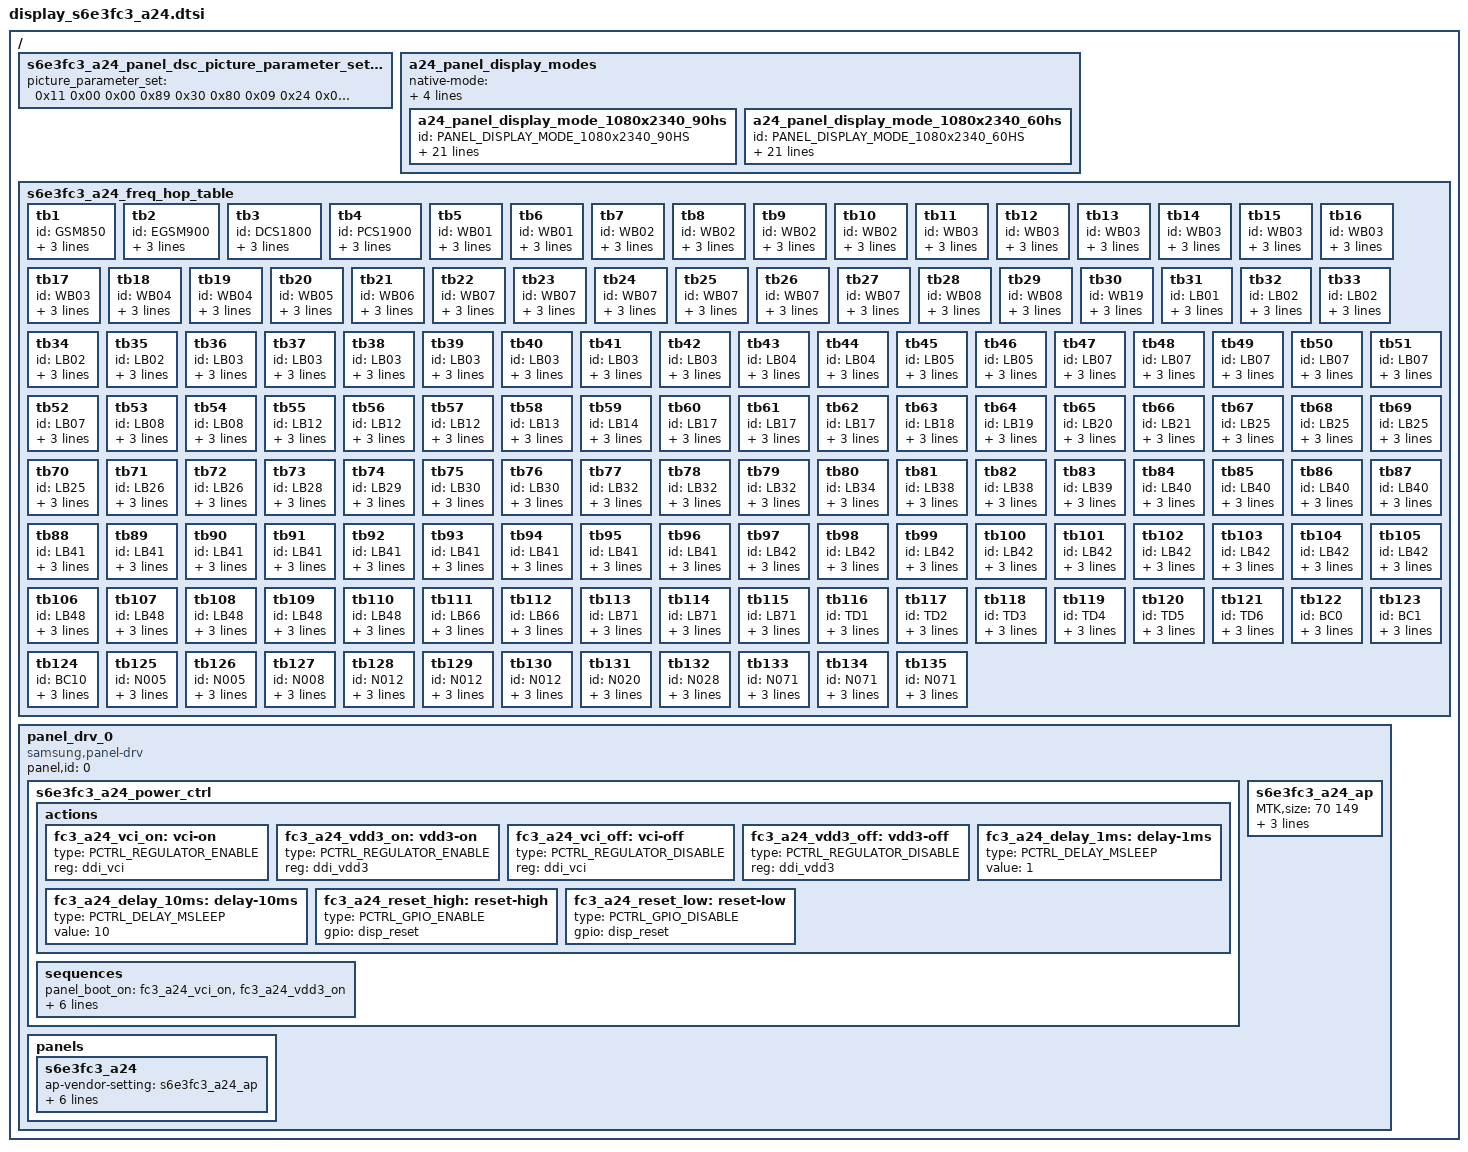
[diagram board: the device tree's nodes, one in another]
/*
 * Samsung Exynos SoC series Panel driver
 *
 * Copyright (c) 2020 Samsung Electronics Co., Ltd
 *
 * This program is free software; you can redistribute it and/or modify
 * it under the terms of the GNU General Public License version 2 as
 * published by the Free Software Foundation.
 */

#include <dt-bindings/display/panel-display.h>
#include <dt-bindings/display/rf-band-id.h>


/ {
	fragment@panel_display_mode {
		target-path = "/";
		__overlay__ {
			s6e3fc3_a24_panel_dsc_picture_parameter_set_default:
			s6e3fc3_a24_panel_dsc_picture_parameter_set_default {
					picture_parameter_set = /bits/ 8 <
						0x11 0x00 0x00 0x89 0x30 0x80 0x09 0x24
						0x04 0x38 0x00 0x1E 0x02 0x1C 0x02 0x1C
						0x02 0x00 0x02 0x0E 0x00 0x20 0x02 0xE3
						0x00 0x07 0x00 0x0C 0x03 0x50 0x03 0x64
						0x18 0x00 0x10 0xF0 0x03 0x0C 0x20 0x00
						0x06 0x0B 0x0B 0x33 0x0E 0x1C 0x2A 0x38
						0x46 0x54 0x62 0x69 0x70 0x77 0x79 0x7B
						0x7D 0x7E 0x01 0x02 0x01 0x00 0x09 0x40
						0x09 0xBE 0x19 0xFC 0x19 0xFA 0x19 0xF8
						0x1A 0x38 0x1A 0x78 0x1A 0xB6 0x2A 0xF6
						0x2B 0x34 0x2B 0x74 0x3B 0x74 0x6B 0xF4
						0x00 0x00 0x00 0x00 0x00 0x00 0x00 0x00
						0x00 0x00 0x00 0x00 0x00 0x00 0x00 0x00
						0x00 0x00 0x00 0x00 0x00 0x00 0x00 0x00
						0x00 0x00 0x00 0x00 0x00 0x00 0x00 0x00
						0x00 0x00 0x00 0x00 0x00 0x00 0x00 0x00
					>;
			};
			a24_panel_display_modes:
			a24_panel_display_modes {
				native-mode = <&a24_panel_display_mode_1080x2340_60hs>;
				exposed-mode = <
					&a24_panel_display_mode_1080x2340_60hs
					&a24_panel_display_mode_1080x2340_90hs
				>;

				/* fhd */
				a24_panel_display_mode_1080x2340_90hs:
				a24_panel_display_mode_1080x2340_90hs {
					id = PANEL_DISPLAY_MODE_1080x2340_90HS;
					width = <1080>;
					height = <2340>;
					/* timing parameters */
					refresh_rate = <90>;			/* logical refresh rate */
					refresh_mode = <REFRESH_MODE_HS>;
					panel_refresh_rate = <90>;		/* panel internal refresh rate */
					panel_refresh_mode = <PANEL_REFRESH_MODE_HS>;
					panel_te_st = <0>;				/* te rising */
					panel_te_ed = <0>;				/* te falling */
					panel_te_sw_skip_count = <0>;	/* s/w te modulation */
					panel_te_hw_skip_count = <0>;	/* h/w te modulation */
					panel_h_porch = <2 2 2>;
					panel_v_porch = <2 2 2>;	/* panel vbp:12, vfp:4, but for ap vblank set vbp:12+4, vfp:0 */
					/* dsc parameters */
					dsc_en = <1>;			/* 0:Disable, 1:Enable */
					dsc_cnt = <1>;			/* used DSC count */
					dsc_slice_num = <2>;	/* count of dsc slice */
					dsc_slice_w = <540>;	/* width of dsc slice */
					dsc_slice_h = <30>;	/* height of dsc slice */
					dsc_picture_parameter_set = <&s6e3fc3_a24_panel_dsc_picture_parameter_set_default>;

					/* dsi parameters */
					cmd_lp_ref = <2107>;
										/*qos parameters */
					disp_qos_fps = <90>;
				};

				a24_panel_display_mode_1080x2340_60hs:
				a24_panel_display_mode_1080x2340_60hs {
					id = PANEL_DISPLAY_MODE_1080x2340_60HS;
					width = <1080>;
					height = <2340>;
					/* timing parameters */
					refresh_rate = <60>;			/* logical refresh rate */
					refresh_mode = <REFRESH_MODE_HS>;
					panel_refresh_rate = <60>;		/* panel internal refresh rate */
					panel_refresh_mode = <PANEL_REFRESH_MODE_HS>;
					panel_te_st = <0>;				/* te rising */
					panel_te_ed = <0>;				/* te falling */
					panel_te_sw_skip_count = <0>;	/* s/w te modulation */
					panel_te_hw_skip_count = <0>;	/* h/w te modulation */
					panel_h_porch = <2 2 2>;
					panel_v_porch = <2 2 2>;	/* panel vbp:12, vfp:2420, but for ap vblank set vbp:12+2420, vfp:0 */
					/* dsc parameters */
					dsc_en = <1>;			/* 0:Disable, 1:Enable */
					dsc_cnt = <1>;			/* used DSC count */
					dsc_slice_num = <2>;	/* count of dsc slice */
					dsc_slice_w = <540>;	/* width of dsc slice */
					dsc_slice_h = <30>;	/* height of dsc slice */
					dsc_picture_parameter_set = <&s6e3fc3_a24_panel_dsc_picture_parameter_set_default>;
					/* dsi parameters */
					cmd_lp_ref = <7991>;
					/*qos parameters */
					disp_qos_fps = <90>;
				};


			};
		};
	};
};

/ {
	fragment@freq_hop {
		target-path = "/";
		__overlay__ {
			s6e3fc3_a24_freq_hop_table: s6e3fc3_a24_freq_hop_table {
				tb1 { id = <GSM850>; range = <0 0>; dsi_freq = <824000>; osc_freq = <0>; };
				tb2 { id = <EGSM900>; range = <0 0>; dsi_freq = <824000>; osc_freq = <0>; };
				tb3 { id = <DCS1800>; range = <0 0>; dsi_freq = <822000>; osc_freq = <0>; };
				tb4 { id = <PCS1900>; range = <0 0>; dsi_freq = <806000>; osc_freq = <0>; };
				tb5 { id = <WB01>; range = <10562 10653>; dsi_freq = <822000>; osc_freq = <0>; };
				tb6 { id = <WB01>; range = <10654 10838>; dsi_freq = <806000>; osc_freq = <0>; };
				tb7 { id = <WB02>; range = <9662 9709>; dsi_freq = <824000>; osc_freq = <0>; };
				tb8 { id = <WB02>; range = <9710 9836>; dsi_freq = <806000>; osc_freq = <0>; };
				tb9 { id = <WB02>; range = <9837 9859>; dsi_freq = <822000>; osc_freq = <0>; };
				tb10 { id = <WB02>; range = <9860 9938>; dsi_freq = <824000>; osc_freq = <0>; };
				tb11 { id = <WB03>; range = <1162 1267>; dsi_freq = <822000>; osc_freq = <0>; };
				tb12 { id = <WB03>; range = <1268 1272>; dsi_freq = <806000>; osc_freq = <0>; };
				tb13 { id = <WB03>; range = <1273 1297>; dsi_freq = <822000>; osc_freq = <0>; };
				tb14 { id = <WB03>; range = <1298 1319>; dsi_freq = <824000>; osc_freq = <0>; };
				tb15 { id = <WB03>; range = <1320 1447>; dsi_freq = <806000>; osc_freq = <0>; };
				tb16 { id = <WB03>; range = <1448 1469>; dsi_freq = <822000>; osc_freq = <0>; };
				tb17 { id = <WB03>; range = <1470 1513>; dsi_freq = <824000>; osc_freq = <0>; };
				tb18 { id = <WB04>; range = <1537 1628>; dsi_freq = <822000>; osc_freq = <0>; };
				tb19 { id = <WB04>; range = <1629 1738>; dsi_freq = <806000>; osc_freq = <0>; };
				tb20 { id = <WB05>; range = <4357 4458>; dsi_freq = <806000>; osc_freq = <0>; };
				tb21 { id = <WB06>; range = <4387 4413>; dsi_freq = <806000>; osc_freq = <0>; };
				tb22 { id = <WB07>; range = <2237 2297>; dsi_freq = <822000>; osc_freq = <0>; };
				tb23 { id = <WB07>; range = <2298 2342>; dsi_freq = <806000>; osc_freq = <0>; };
				tb24 { id = <WB07>; range = <2343 2407>; dsi_freq = <822000>; osc_freq = <0>; };
				tb25 { id = <WB07>; range = <2408 2439>; dsi_freq = <824000>; osc_freq = <0>; };
				tb26 { id = <WB07>; range = <2440 2557>; dsi_freq = <806000>; osc_freq = <0>; };
				tb27 { id = <WB07>; range = <2558 2563>; dsi_freq = <822000>; osc_freq = <0>; };
				tb28 { id = <WB08>; range = <2937 3000>; dsi_freq = <806000>; osc_freq = <0>; };
				tb29 { id = <WB08>; range = <3001 3088>; dsi_freq = <824000>; osc_freq = <0>; };
				tb30 { id = <WB19>; range = <712 763>; dsi_freq = <806000>; osc_freq = <0>; };
				tb31 { id = <LB01>; range = <0 599>; dsi_freq = <822000>; osc_freq = <0>; };
				tb32 { id = <LB02>; range = <600 719>; dsi_freq = <824000>; osc_freq = <0>; };
				tb33 { id = <LB02>; range = <720 972>; dsi_freq = <806000>; osc_freq = <0>; };
				tb34 { id = <LB02>; range = <973 1019>; dsi_freq = <822000>; osc_freq = <0>; };
				tb35 { id = <LB02>; range = <1020 1199>; dsi_freq = <824000>; osc_freq = <0>; };
				tb36 { id = <LB03>; range = <1200 1434>; dsi_freq = <822000>; osc_freq = <0>; };
				tb37 { id = <LB03>; range = <1435 1444>; dsi_freq = <806000>; osc_freq = <0>; };
				tb38 { id = <LB03>; range = <1445 1494>; dsi_freq = <822000>; osc_freq = <0>; };
				tb39 { id = <LB03>; range = <1495 1600>; dsi_freq = <824000>; osc_freq = <0>; };
				tb40 { id = <LB03>; range = <1601 1794>; dsi_freq = <806000>; osc_freq = <0>; };
				tb41 { id = <LB03>; range = <1795 1839>; dsi_freq = <822000>; osc_freq = <0>; };
				tb42 { id = <LB03>; range = <1840 1949>; dsi_freq = <824000>; osc_freq = <0>; };
				tb43 { id = <LB04>; range = <1950 2157>; dsi_freq = <822000>; osc_freq = <0>; };
				tb44 { id = <LB04>; range = <2158 2399>; dsi_freq = <806000>; osc_freq = <0>; };
				tb45 { id = <LB05>; range = <2400 2627>; dsi_freq = <806000>; osc_freq = <0>; };
				tb46 { id = <LB05>; range = <2628 2649>; dsi_freq = <822000>; osc_freq = <0>; };
				tb47 { id = <LB07>; range = <2750 2894>; dsi_freq = <822000>; osc_freq = <0>; };
				tb48 { id = <LB07>; range = <2895 2984>; dsi_freq = <806000>; osc_freq = <0>; };
				tb49 { id = <LB07>; range = <2985 3114>; dsi_freq = <822000>; osc_freq = <0>; };
				tb50 { id = <LB07>; range = <3115 3179>; dsi_freq = <824000>; osc_freq = <0>; };
				tb51 { id = <LB07>; range = <3180 3414>; dsi_freq = <806000>; osc_freq = <0>; };
				tb52 { id = <LB07>; range = <3415 3449>; dsi_freq = <822000>; osc_freq = <0>; };
				tb53 { id = <LB08>; range = <3450 3600>; dsi_freq = <806000>; osc_freq = <0>; };
				tb54 { id = <LB08>; range = <3601 3799>; dsi_freq = <824000>; osc_freq = <0>; };
				tb55 { id = <LB12>; range = <5010 5062>; dsi_freq = <806000>; osc_freq = <0>; };
				tb56 { id = <LB12>; range = <5063 5079>; dsi_freq = <822000>; osc_freq = <0>; };
				tb57 { id = <LB12>; range = <5080 5179>; dsi_freq = <824000>; osc_freq = <0>; };
				tb58 { id = <LB13>; range = <5180 5279>; dsi_freq = <824000>; osc_freq = <0>; };
				tb59 { id = <LB14>; range = <5280 5379>; dsi_freq = <824000>; osc_freq = <0>; };
				tb60 { id = <LB17>; range = <5730 5732>; dsi_freq = <806000>; osc_freq = <0>; };
				tb61 { id = <LB17>; range = <5733 5749>; dsi_freq = <822000>; osc_freq = <0>; };
				tb62 { id = <LB17>; range = <5750 5849>; dsi_freq = <824000>; osc_freq = <0>; };
				tb63 { id = <LB18>; range = <5850 5999>; dsi_freq = <806000>; osc_freq = <0>; };
				tb64 { id = <LB19>; range = <6000 6149>; dsi_freq = <806000>; osc_freq = <0>; };
				tb65 { id = <LB20>; range = <6150 6449>; dsi_freq = <822000>; osc_freq = <0>; };
				tb66 { id = <LB21>; range = <6450 6599>; dsi_freq = <824000>; osc_freq = <0>; };
				tb67 { id = <LB25>; range = <8040 8159>; dsi_freq = <824000>; osc_freq = <0>; };
				tb68 { id = <LB25>; range = <8160 8412>; dsi_freq = <806000>; osc_freq = <0>; };
				tb69 { id = <LB25>; range = <8413 8459>; dsi_freq = <822000>; osc_freq = <0>; };
				tb70 { id = <LB25>; range = <8460 8689>; dsi_freq = <824000>; osc_freq = <0>; };
				tb71 { id = <LB26>; range = <8690 9017>; dsi_freq = <806000>; osc_freq = <0>; };
				tb72 { id = <LB26>; range = <9018 9039>; dsi_freq = <822000>; osc_freq = <0>; };
				tb73 { id = <LB28>; range = <9210 9659>; dsi_freq = <824000>; osc_freq = <0>; };
				tb74 { id = <LB29>; range = <9660 9769>; dsi_freq = <806000>; osc_freq = <0>; };
				tb75 { id = <LB30>; range = <9770 9809>; dsi_freq = <824000>; osc_freq = <0>; };
				tb76 { id = <LB30>; range = <9810 9869>; dsi_freq = <806000>; osc_freq = <0>; };
				tb77 { id = <LB32>; range = <9920 9934>; dsi_freq = <806000>; osc_freq = <0>; };
				tb78 { id = <LB32>; range = <9935 9969>; dsi_freq = <822000>; osc_freq = <0>; };
				tb79 { id = <LB32>; range = <9970 10359>; dsi_freq = <824000>; osc_freq = <0>; };
				tb80 { id = <LB34>; range = <36200 36349>; dsi_freq = <824000>; osc_freq = <0>; };
				tb81 { id = <LB38>; range = <37750 38094>; dsi_freq = <806000>; osc_freq = <0>; };
				tb82 { id = <LB38>; range = <38095 38249>; dsi_freq = <822000>; osc_freq = <0>; };
				tb83 { id = <LB39>; range = <38250 38649>; dsi_freq = <824000>; osc_freq = <0>; };
				tb84 { id = <LB40>; range = <38650 39189>; dsi_freq = <824000>; osc_freq = <0>; };
				tb85 { id = <LB40>; range = <39190 39432>; dsi_freq = <806000>; osc_freq = <0>; };
				tb86 { id = <LB40>; range = <39433 39489>; dsi_freq = <822000>; osc_freq = <0>; };
				tb87 { id = <LB40>; range = <39490 39649>; dsi_freq = <824000>; osc_freq = <0>; };
				tb88 { id = <LB41>; range = <39650 39727>; dsi_freq = <806000>; osc_freq = <0>; };
				tb89 { id = <LB41>; range = <39728 40027>; dsi_freq = <822000>; osc_freq = <0>; };
				tb90 { id = <LB41>; range = <40028 40734>; dsi_freq = <806000>; osc_freq = <0>; };
				tb91 { id = <LB41>; range = <40735 41034>; dsi_freq = <822000>; osc_freq = <0>; };
				tb92 { id = <LB41>; range = <41035 41124>; dsi_freq = <806000>; osc_freq = <0>; };
				tb93 { id = <LB41>; range = <41125 41254>; dsi_freq = <822000>; osc_freq = <0>; };
				tb94 { id = <LB41>; range = <41255 41319>; dsi_freq = <824000>; osc_freq = <0>; };
				tb95 { id = <LB41>; range = <41320 41554>; dsi_freq = <806000>; osc_freq = <0>; };
				tb96 { id = <LB41>; range = <41555 41589>; dsi_freq = <822000>; osc_freq = <0>; };
				tb97 { id = <LB42>; range = <41590 41695>; dsi_freq = <806000>; osc_freq = <0>; };
				tb98 { id = <LB42>; range = <41696 41995>; dsi_freq = <822000>; osc_freq = <0>; };
				tb99 { id = <LB42>; range = <41996 42165>; dsi_freq = <806000>; osc_freq = <0>; };
				tb100 { id = <LB42>; range = <42166 42375>; dsi_freq = <822000>; osc_freq = <0>; };
				tb101 { id = <LB42>; range = <42376 42460>; dsi_freq = <824000>; osc_freq = <0>; };
				tb102 { id = <LB42>; range = <42461 42675>; dsi_freq = <806000>; osc_freq = <0>; };
				tb103 { id = <LB42>; range = <42676 42760>; dsi_freq = <822000>; osc_freq = <0>; };
				tb104 { id = <LB42>; range = <42761 43490>; dsi_freq = <824000>; osc_freq = <0>; };
				tb105 { id = <LB42>; range = <43491 43589>; dsi_freq = <806000>; osc_freq = <0>; };
				tb106 { id = <LB48>; range = <55240 55640>; dsi_freq = <824000>; osc_freq = <0>; };
				tb107 { id = <LB48>; range = <55641 55852>; dsi_freq = <806000>; osc_freq = <0>; };
				tb108 { id = <LB48>; range = <55853 55940>; dsi_freq = <822000>; osc_freq = <0>; };
				tb109 { id = <LB48>; range = <55941 56415>; dsi_freq = <824000>; osc_freq = <0>; };
				tb110 { id = <LB48>; range = <56416 56739>; dsi_freq = <806000>; osc_freq = <0>; };
				tb111 { id = <LB66>; range = <66436 66643>; dsi_freq = <822000>; osc_freq = <0>; };
				tb112 { id = <LB66>; range = <66644 67335>; dsi_freq = <806000>; osc_freq = <0>; };
				tb113 { id = <LB71>; range = <68586 68730>; dsi_freq = <806000>; osc_freq = <0>; };
				tb114 { id = <LB71>; range = <68731 68745>; dsi_freq = <822000>; osc_freq = <0>; };
				tb115 { id = <LB71>; range = <68746 68935>; dsi_freq = <824000>; osc_freq = <0>; };
				tb116 { id = <TD1>; range = <0 0>; dsi_freq = <824000>; osc_freq = <0>; };
				tb117 { id = <TD2>; range = <0 0>; dsi_freq = <806000>; osc_freq = <0>; };
				tb118 { id = <TD3>; range = <0 0>; dsi_freq = <824000>; osc_freq = <0>; };
				tb119 { id = <TD4>; range = <0 0>; dsi_freq = <806000>; osc_freq = <0>; };
				tb120 { id = <TD5>; range = <0 0>; dsi_freq = <806000>; osc_freq = <0>; };
				tb121 { id = <TD6>; range = <0 0>; dsi_freq = <824000>; osc_freq = <0>; };
				tb122 { id = <BC0>; range = <0 0>; dsi_freq = <824000>; osc_freq = <0>; };
				tb123 { id = <BC1>; range = <0 0>; dsi_freq = <806000>; osc_freq = <0>; };
				tb124 { id = <BC10>; range = <0 0>; dsi_freq = <806000>; osc_freq = <0>; };
				tb125 { id = <N005>; range = <173800 176340>; dsi_freq = <806000>; osc_freq = <0>; };
				tb126 { id = <N005>; range = <176341 178780>; dsi_freq = <822000>; osc_freq = <0>; };
				tb127 { id = <N008>; range = <185000 191980>; dsi_freq = <824000>; osc_freq = <0>; };
				tb128 { id = <N012>; range = <145800 148840>; dsi_freq = <806000>; osc_freq = <0>; };
				tb129 { id = <N012>; range = <148841 149180>; dsi_freq = <822000>; osc_freq = <0>; };
				tb130 { id = <N012>; range = <149181 149200>; dsi_freq = <824000>; osc_freq = <0>; };
				tb131 { id = <N020>; range = <158200 164180>; dsi_freq = <822000>; osc_freq = <0>; };
				tb132 { id = <N028>; range = <151600 160580>; dsi_freq = <824000>; osc_freq = <0>; };
				tb133 { id = <N071>; range = <123400 128280>; dsi_freq = <806000>; osc_freq = <0>; };
				tb134 { id = <N071>; range = <128281 128580>; dsi_freq = <822000>; osc_freq = <0>; };
				tb135 { id = <N071>; range = <128581 130380>; dsi_freq = <824000>; osc_freq = <0>; };
			};
		};
	};
};

/ {
	fragment@panel_drv {
		target-path = "/";
		__overlay__ {
			panel_drv_0: panel_drv_0 {
				status = "okay";
				compatible = "samsung,panel-drv";
				panel,id = <0>;

				s6e3fc3_a24_power_ctrl:
				s6e3fc3_a24_power_ctrl {
					actions {
						fc3_a24_vci_on: vci-on {
							type = <PCTRL_REGULATOR_ENABLE>;
							reg = <&ddi_vci>;
						};
						fc3_a24_vdd3_on: vdd3-on {
							type = <PCTRL_REGULATOR_ENABLE>;
							reg = <&ddi_vdd3>;
						};
						fc3_a24_vci_off: vci-off {
							type = <PCTRL_REGULATOR_DISABLE>;
							reg = <&ddi_vci>;
						};
						fc3_a24_vdd3_off: vdd3-off {
							type = <PCTRL_REGULATOR_DISABLE>;
							reg = <&ddi_vdd3>;
						};
						fc3_a24_delay_1ms: delay-1ms {
							type = <PCTRL_DELAY_MSLEEP>;
							value = <1>;
						};
						fc3_a24_delay_10ms: delay-10ms {
							type = <PCTRL_DELAY_MSLEEP>;
							value = <10>;
						};
						fc3_a24_reset_high: reset-high {
							type = <PCTRL_GPIO_ENABLE>;
							gpio = <&disp_reset>;
						};
						fc3_a24_reset_low: reset-low {
							type = <PCTRL_GPIO_DISABLE>;
							gpio = <&disp_reset>;
						};
					};
					sequences {
						panel_boot_on = <&fc3_a24_vci_on &fc3_a24_vdd3_on>;
						panel_power_on = <&fc3_a24_vci_on &fc3_a24_vdd3_on &fc3_a24_delay_10ms &fc3_a24_reset_high &fc3_a24_delay_10ms>;
						panel_power_off = <&fc3_a24_reset_low &fc3_a24_delay_1ms &fc3_a24_vci_off &fc3_a24_delay_10ms &fc3_a24_vdd3_off>;
					};
				};

				s6e3fc3_a24_ap:s6e3fc3_a24_ap {
					MTK,size = <70 149>; /* 69.796 mm x 149.058 mm */
					MTK,timing,dsi-hs-clk = <806>; //orig: 1108
					MTK,data_lane = <4>;		/* number of using data lane */
					MTK,multi_drop = <0>;
				};

				panels {
					s6e3fc3_a24: s6e3fc3_a24 {
						ap-vendor-setting = <&s6e3fc3_a24_ap>;
						display-mode = <&a24_panel_display_modes>;
						power-ctrl = <&s6e3fc3_a24_power_ctrl>;
						dqe-suffix = "s6e3fc3_a24";
						freq-hop = <&s6e3fc3_a24_freq_hop_table>;
						id-mask = <
							PANEL_ID(0x000000) PANEL_MASK(0x000000)
						>;
					};
				};
			};
		};
	};
};

